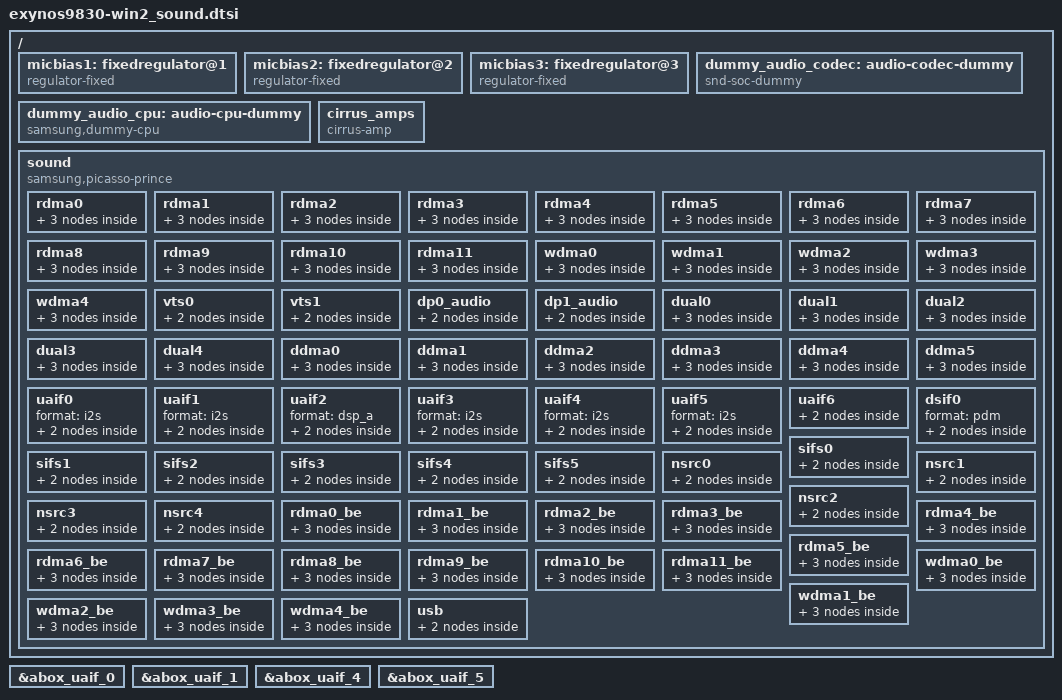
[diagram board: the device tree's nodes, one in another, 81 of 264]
/*
 * Samsung's Picasso SoC soundcard device tree source
 *
 * Copyright (c) 2019 Samsung Electronics Co., Ltd.
 *		http://www.samsung.com
 *
 * This program is free software; you can redistribute it and/or modify
 * it under the terms of the GNU General Public License version 2 as
 * published by the Free Software Foundation.
*/

/ {
	fragment@model {
		target-path = "/";
		__overlay__ {
			micbias1: fixedregulator@1 {
				compatible = "regulator-fixed";
				regulator-name = "main_micbias_1p8";
				regulator-min-microvolt = <1800000>;
				regulator-max-microvolt = <1800000>;
				gpio = <&gpp4 1 0>;
				enable-active-high;
				vin-supply = <&buck12_reg>;
			};

			micbias2: fixedregulator@2 {
				compatible = "regulator-fixed";
				regulator-name = "sub_micbias_1p8";
				regulator-min-microvolt = <1800000>;
				regulator-max-microvolt = <1800000>;
				vin-supply = <&ldo13_reg>;
			};

			micbias3: fixedregulator@3 {
				compatible = "regulator-fixed";
				regulator-name = "3rd_micbias_1p8";
				regulator-min-microvolt = <1800000>;
				regulator-max-microvolt = <1800000>;
				vin-supply = <&ldo14_reg>;
			};

			dummy_audio_codec: audio-codec-dummy {
				compatible = "snd-soc-dummy";
			#sound-dai-cells = <0>;
			};

			dummy_audio_cpu: audio-cpu-dummy {
				compatible = "samsung,dummy-cpu";
			#sound-dai-cells = <0>;
			};

			cirrus_amps {
				compatible = "cirrus-amp";
				cirrus,num-amps = <3>;
				cirrus,amps = <&cs35l41_1 &cs35l41_2 &cs35l41_3>;
			};

			sound {
				compatible = "samsung,picasso-prince";

				clock-names = "xclkout";
				clocks = <&clock OSC_AUD>;

				MICBIAS1-supply = <&micbias1>;
				MICBIAS2-supply = <&micbias2>;
				MICBIAS3-supply = <&micbias3>;

				samsung,routing = "DMIC1", "MICBIAS1",
					"DMIC2", "MICBIAS2",
					"DMIC3", "MICBIAS3",
					"RECEIVER", "Left AMP SPK",
					"SPEAKER", "Right AMP SPK",
					"BLUETOOTH SPK", "ABOX UAIF3 Playback",
					"ABOX UAIF3 Capture", "BLUETOOTH MIC",
					"USB SPK", "ABOX USB Playback",
					"ABOX USB Capture", "USB MIC",
					"VTS Virtual Output", "VTS Virtual Output Mux",
					"PAD DPDM", "DMIC1",
					"PAD DPDM", "DMIC2",
					"PAD DPDM", "DMIC3";
				samsung,codec = <&cs35l41_1 &cs35l41_2 &cs35l41_3 &vts>;
				samsung,prefix = "SPKL", "SPKU", "RCV", "VTS";
				samsung,aux = <&abox_effect &abox_tplg>;

				rdma0 {
					cpu {
						sound-dai = <&abox_rdma_0 0>;
					};
					platform {
						sound-dai = <&abox_rdma_0 0>;
					};
					codec {
						sound-dai = <&dummy_audio_codec>;
					};
				};
				rdma1 {
					cpu {
						sound-dai = <&abox_rdma_1 0>;
					};
					platform {
						sound-dai = <&abox_rdma_1 0>;
					};
					codec {
						sound-dai = <&dummy_audio_codec>;
					};
				};
				rdma2 {
					cpu {
						sound-dai = <&abox_rdma_2 0>;
					};
					platform {
						sound-dai = <&abox_rdma_2 0>;
					};
					codec {
						sound-dai = <&dummy_audio_codec>;
					};
				};
				rdma3 {
					cpu {
						sound-dai = <&abox_rdma_3 0>;
					};
					platform {
						sound-dai = <&abox_rdma_3 0>;
					};
					codec {
						sound-dai = <&dummy_audio_codec>;
					};
				};
				rdma4 {
					cpu {
						sound-dai = <&abox_rdma_4 0>;
					};
					platform {
						sound-dai = <&abox_rdma_4 0>;
					};
					codec {
						sound-dai = <&dummy_audio_codec>;
					};
				};
				rdma5 {
					cpu {
						sound-dai = <&abox_rdma_5 0>;
					};
					platform {
						sound-dai = <&abox_rdma_5 0>;
					};
					codec {
						sound-dai = <&dummy_audio_codec>;
					};
				};
				rdma6 {
					cpu {
						sound-dai = <&abox_rdma_6 0>;
					};
					platform {
						sound-dai = <&abox_rdma_6 0>;
					};
					codec {
						sound-dai = <&dummy_audio_codec>;
					};
				};
				rdma7 {
					cpu {
						sound-dai = <&abox_rdma_7 0>;
					};
					platform {
						sound-dai = <&abox_rdma_7 0>;
					};
					codec {
						sound-dai = <&dummy_audio_codec>;
					};
				};
				rdma8 {
					cpu {
						sound-dai = <&abox_rdma_8 0>;
					};
					platform {
						sound-dai = <&abox_rdma_8 0>;
					};
					codec {
						sound-dai = <&dummy_audio_codec>;
					};
				};
				rdma9 {
					cpu {
						sound-dai = <&abox_rdma_9 0>;
					};
					platform {
						sound-dai = <&abox_rdma_9 0>;
					};
					codec {
						sound-dai = <&dummy_audio_codec>;
					};
				};
				rdma10 {
					cpu {
						sound-dai = <&abox_rdma_10 0>;
					};
					platform {
						sound-dai = <&abox_rdma_10 0>;
					};
					codec {
						sound-dai = <&dummy_audio_codec>;
					};
				};
				rdma11 {
					cpu {
						sound-dai = <&abox_rdma_11 0>;
					};
					platform {
						sound-dai = <&abox_rdma_11 0>;
					};
					codec {
						sound-dai = <&dummy_audio_codec>;
					};
				};
				wdma0 {
					cpu {
						sound-dai = <&abox_wdma_0 0>;
					};
					platform {
						sound-dai = <&abox_wdma_0 0>;
					};
					codec {
						sound-dai = <&dummy_audio_codec>;
					};
				};
				wdma1 {
					cpu {
						sound-dai = <&abox_wdma_1 0>;
					};
					platform {
						sound-dai = <&abox_wdma_1 0>;
					};
					codec {
						sound-dai = <&dummy_audio_codec>;
					};
				};
				wdma2 {
					cpu {
						sound-dai = <&abox_wdma_2 0>;
					};
					platform {
						sound-dai = <&abox_wdma_2 0>;
					};
					codec {
						sound-dai = <&dummy_audio_codec>;
					};
				};
				wdma3 {
					cpu {
						sound-dai = <&abox_wdma_3 0>;
					};
					platform {
						sound-dai = <&abox_wdma_3 0>;
					};
					codec {
						sound-dai = <&dummy_audio_codec>;
					};
				};
				wdma4 {
					cpu {
						sound-dai = <&abox_wdma_4 0>;
					};
					platform {
						sound-dai = <&abox_wdma_4 0>;
					};
					codec {
						sound-dai = <&dummy_audio_codec>;
					};
				};
				vts0 {
					cpu {
						sound-dai = <&vts 0>;
					};
					codec {
						sound-dai = <&dummy_audio_codec>;
					};
				};
				vts1 {
					cpu {
						sound-dai = <&vts 1>;
					};
					codec {
						sound-dai = <&dummy_audio_codec>;
					};
				};
				dp0_audio {
					cpu {
						sound-dai = <&displayport_adma 0>;
					};
					codec {
						sound-dai = <&dummy_audio_codec>;
					};
				};
				dp1_audio {
					cpu {
						sound-dai = <&displayport_adma 1 >;
					};
					codec {
						sound-dai = <&dummy_audio_codec>;
					};
				};
				dual0 {
					cpu {
						sound-dai = <&abox_dual_0>;
					};
					platform {
						sound-dai = <&abox_dual_0>;
					};
					codec {
						sound-dai = <&dummy_audio_codec>;
					};
				};
				dual1 {
					cpu {
						sound-dai = <&abox_dual_1>;
					};
					platform {
						sound-dai = <&abox_dual_1>;
					};
					codec {
						sound-dai = <&dummy_audio_codec>;
					};
				};
				dual2 {
					cpu {
						sound-dai = <&abox_dual_2>;
					};
					platform {
						sound-dai = <&abox_dual_2>;
					};
					codec {
						sound-dai = <&dummy_audio_codec>;
					};
				};
				dual3 {
					cpu {
						sound-dai = <&abox_dual_3>;
					};
					platform {
						sound-dai = <&abox_dual_3>;
					};
					codec {
						sound-dai = <&dummy_audio_codec>;
					};
				};
				dual4 {
					cpu {
						sound-dai = <&abox_dual_4>;
					};
					platform {
						sound-dai = <&abox_dual_4>;
					};
					codec {
						sound-dai = <&dummy_audio_codec>;
					};
				};
				ddma0 {
					cpu {
						sound-dai = <&abox_ddma_0>;
					};
					platform {
						sound-dai = <&abox_ddma_0>;
					};
					codec {
						sound-dai = <&dummy_audio_codec>;
					};
				};
				ddma1 {
					cpu {
						sound-dai = <&abox_ddma_1>;
					};
					platform {
						sound-dai = <&abox_ddma_1>;
					};
					codec {
						sound-dai = <&dummy_audio_codec>;
					};
				};
				ddma2 {
					cpu {
						sound-dai = <&abox_ddma_2>;
					};
					platform {
						sound-dai = <&abox_ddma_2>;
					};
					codec {
						sound-dai = <&dummy_audio_codec>;
					};
				};
				ddma3 {
					cpu {
						sound-dai = <&abox_ddma_3>;
					};
					platform {
						sound-dai = <&abox_ddma_3>;
					};
					codec {
						sound-dai = <&dummy_audio_codec>;
					};
				};
				ddma4 {
					cpu {
						sound-dai = <&abox_ddma_4>;
					};
					platform {
						sound-dai = <&abox_ddma_4>;
					};
					codec {
						sound-dai = <&dummy_audio_codec>;
					};
				};
				ddma5 {
					cpu {
						sound-dai = <&abox_ddma_5>;
					};
					platform {
						sound-dai = <&abox_ddma_5>;
					};
					codec {
						sound-dai = <&dummy_audio_codec>;
					};
				};
				uaif0 {
					format = "i2s";
					cpu {
						sound-dai = <&abox_uaif_0>;
					};
					codec {
						sound-dai = <&dummy_audio_codec>;
					};
				};
				uaif1 {
					format = "i2s";
					cpu {
						sound-dai = <&abox_uaif_1>;
					};
					codec {
						sound-dai = <&dummy_audio_codec>;
					};
				};
				uaif2 {
					format = "dsp_a";
					cpu {
						sound-dai = <&abox_uaif_2>;
					};
					codec {
						sound-dai = <&cs35l41_1 0 &cs35l41_2 0 &cs35l41_3 0>;
					};
				};
				uaif3 {
					format = "i2s";
					cpu {
						sound-dai = <&abox_uaif_3>;
					};
					codec {
						sound-dai = <&dummy_audio_codec>;
					};
				};
				uaif4 {
					format = "i2s";
					cpu {
						sound-dai = <&abox_uaif_4>;
					};
					codec {
						sound-dai = <&dummy_audio_codec>;
					};
				};
				uaif5 {
					format = "i2s";
					cpu {
						sound-dai = <&abox_uaif_5>;
					};
					codec {
						sound-dai = <&dummy_audio_codec>;
					};
				};
				uaif6 {
					format = "dsp_a";
					bitclock-master;
					bitclock-inversion;
					frame-master;

					cpu {
						sound-dai = <&abox_uaif_6>;
					};
					codec {
						sound-dai = <&vts_s_lif 0>;
					};
				};
				dsif0 {
					format = "pdm";
					cpu {
						sound-dai = <&abox_dsif>;
					};
					codec {
						sound-dai = <&dummy_audio_codec>;
					};
				};
				sifs0 {
					cpu {
						sound-dai = <&abox 0>;
					};
					codec {
						sound-dai = <&dummy_audio_codec>;
					};
				};
				sifs1 {
					cpu {
						sound-dai = <&abox 1>;
					};
					codec {
						sound-dai = <&dummy_audio_codec>;
					};
				};
				sifs2 {
					cpu {
						sound-dai = <&abox 2>;
					};
					codec {
						sound-dai = <&dummy_audio_codec>;
					};
				};
				sifs3 {
					cpu {
						sound-dai = <&abox 3>;
					};
					codec {
						sound-dai = <&dummy_audio_codec>;
					};
				};
				sifs4 {
					cpu {
						sound-dai = <&abox 4>;
					};
					codec {
						sound-dai = <&dummy_audio_codec>;
					};
				};
				sifs5 {
					cpu {
						sound-dai = <&abox 5>;
					};
					codec {
						sound-dai = <&dummy_audio_codec>;
					};
				};
				nsrc0 {
					cpu {
						sound-dai = <&abox 6>;
					};
					codec {
						sound-dai = <&dummy_audio_codec>;
					};
				};
				nsrc1 {
					cpu {
						sound-dai = <&abox 7>;
					};
					codec {
						sound-dai = <&dummy_audio_codec>;
					};
				};
				nsrc2 {
					cpu {
						sound-dai = <&abox 8>;
					};
					codec {
						sound-dai = <&dummy_audio_codec>;
					};
				};
				nsrc3 {
					cpu {
						sound-dai = <&abox 9>;
					};
					codec {
						sound-dai = <&dummy_audio_codec>;
					};
				};
				nsrc4 {
					cpu {
						sound-dai = <&abox 10>;
					};
					codec {
						sound-dai = <&dummy_audio_codec>;
					};
				};
				rdma0_be {
					cpu {
						sound-dai = <&abox_rdma_0 1>;
					};
					platform {
						sound-dai = <&abox_rdma_0 1>;
					};
					codec {
						sound-dai = <&dummy_audio_codec>;
					};
				};
				rdma1_be {
					cpu {
						sound-dai = <&abox_rdma_1 1>;
					};
					platform {
						sound-dai = <&abox_rdma_1 1>;
					};
					codec {
						sound-dai = <&dummy_audio_codec>;
					};
				};
				rdma2_be {
					cpu {
						sound-dai = <&abox_rdma_2 1>;
					};
					platform {
						sound-dai = <&abox_rdma_2 1>;
					};
					codec {
						sound-dai = <&dummy_audio_codec>;
					};
				};
				rdma3_be {
					cpu {
						sound-dai = <&abox_rdma_3 1>;
					};
					platform {
						sound-dai = <&abox_rdma_3 1>;
					};
					codec {
						sound-dai = <&dummy_audio_codec>;
					};
				};
				rdma4_be {
					cpu {
						sound-dai = <&abox_rdma_4 1>;
					};
					platform {
						sound-dai = <&abox_rdma_4 1>;
					};
					codec {
						sound-dai = <&dummy_audio_codec>;
					};
				};
				rdma5_be {
					cpu {
						sound-dai = <&abox_rdma_5 1>;
					};
					platform {
						sound-dai = <&abox_rdma_5 1>;
					};
					codec {
						sound-dai = <&dummy_audio_codec>;
					};
				};
				rdma6_be {
					cpu {
						sound-dai = <&abox_rdma_6 1>;
					};
					platform {
						sound-dai = <&abox_rdma_6 1>;
					};
					codec {
						sound-dai = <&dummy_audio_codec>;
					};
				};
				rdma7_be {
					cpu {
						sound-dai = <&abox_rdma_7 1>;
					};
					platform {
						sound-dai = <&abox_rdma_7 1>;
					};
					codec {
						sound-dai = <&dummy_audio_codec>;
					};
				};
				rdma8_be {
					cpu {
						sound-dai = <&abox_rdma_8 1>;
					};
					platform {
						sound-dai = <&abox_rdma_8 1>;
					};
					codec {
						sound-dai = <&dummy_audio_codec>;
					};
				};
				rdma9_be {
					cpu {
						sound-dai = <&abox_rdma_9 1>;
					};
					platform {
						sound-dai = <&abox_rdma_9 1>;
					};
					codec {
						sound-dai = <&dummy_audio_codec>;
					};
				};
				rdma10_be {
					cpu {
						sound-dai = <&abox_rdma_10 1>;
					};
					platform {
						sound-dai = <&abox_rdma_10 1>;
					};
					codec {
						sound-dai = <&dummy_audio_codec>;
					};
				};
				rdma11_be {
					cpu {
						sound-dai = <&abox_rdma_11 1>;
					};
					platform {
						sound-dai = <&abox_rdma_11 1>;
					};
					codec {
						sound-dai = <&dummy_audio_codec>;
					};
				};
				wdma0_be {
					cpu {
						sound-dai = <&abox_wdma_0 1>;
					};
					platform {
						sound-dai = <&abox_wdma_0 1>;
					};
					codec {
						sound-dai = <&dummy_audio_codec>;
					};
				};
				wdma1_be {
					cpu {
						sound-dai = <&abox_wdma_1 1>;
					};
					platform {
						sound-dai = <&abox_wdma_1 1>;
					};
					codec {
						sound-dai = <&dummy_audio_codec>;
					};
				};
				wdma2_be {
					cpu {
						sound-dai = <&abox_wdma_2 1>;
					};
					platform {
						sound-dai = <&abox_wdma_2 1>;
					};
					codec {
						sound-dai = <&dummy_audio_codec>;
					};
				};
				wdma3_be {
					cpu {
						sound-dai = <&abox_wdma_3 1>;
					};
					platform {
						sound-dai = <&abox_wdma_3 1>;
					};
					codec {
						sound-dai = <&dummy_audio_codec>;
					};
				};
				wdma4_be {
					cpu {
						sound-dai = <&abox_wdma_4 1>;
					};
					platform {
						sound-dai = <&abox_wdma_4 1>;
					};
					codec {
						sound-dai = <&dummy_audio_codec>;
					};
				};
				usb {
					cpu {
						sound-dai = <&abox 16>;
					};
					codec {
						sound-dai = <&dummy_audio_codec>;
					};
				};
			};
		}; /* end of __overlay__ */
	}; /* end of fragment */
}; /* end of root */

&abox_uaif_0 {
	pinctrl-names;
};

&abox_uaif_1 {
	pinctrl-names;
};

&abox_uaif_4 {
	pinctrl-names;
};

&abox_uaif_5 {
	pinctrl-names;
};
